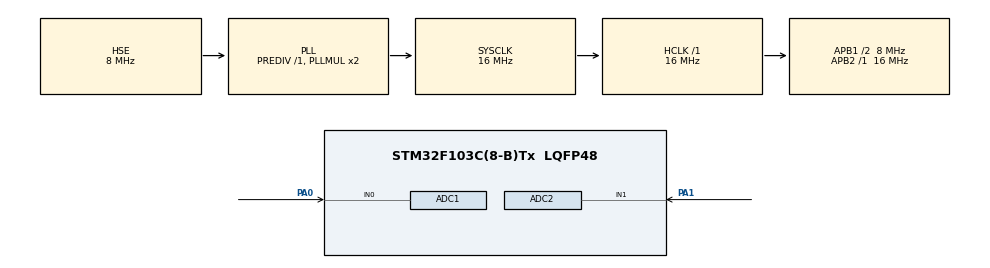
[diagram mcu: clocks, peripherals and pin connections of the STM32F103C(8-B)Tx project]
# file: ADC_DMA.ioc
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ADC1.Channel-0\#ChannelRegularConversion=ADC_CHANNEL_0
ADC1.ContinuousConvMode=ENABLE
ADC1.Mode=ADC_DUALMODE_REGSIMULT
ADC1.NbrOfConversion=1
ADC1.NbrOfConversionFlag=1
ADC1.Rank-0\#ChannelRegularConversion=1
ADC1.SamplingTime-0\#ChannelRegularConversion=ADC_SAMPLETIME_239CYCLES_5
ADC1.master=1
ADC2.Channel-0\#ChannelRegularConversion=ADC_CHANNEL_1
ADC2.ContinuousConvMode=ENABLE
ADC2.Mode=ADC_DUALMODE_REGSIMULT
ADC2.NbrOfConversionFlag=1
ADC2.Rank-0\#ChannelRegularConversion=1
ADC2.SamplingTime-0\#ChannelRegularConversion=ADC_SAMPLETIME_239CYCLES_5
Dma.ADC1.0.Direction=DMA_PERIPH_TO_MEMORY
Dma.ADC1.0.Instance=DMA1_Channel1
Dma.ADC1.0.MemDataAlignment=DMA_MDATAALIGN_WORD
Dma.ADC1.0.MemInc=DMA_MINC_ENABLE
Dma.ADC1.0.Mode=DMA_NORMAL
Dma.ADC1.0.PeriphDataAlignment=DMA_PDATAALIGN_WORD
Dma.ADC1.0.PeriphInc=DMA_PINC_DISABLE
Dma.ADC1.0.Priority=DMA_PRIORITY_LOW
Dma.Request0=ADC1
Mcu.Family=STM32F1
Mcu.Name=STM32F103C(8-B)Tx
Mcu.Package=LQFP48
NVIC.DMA1_Channel1_IRQn=true\:0\:0\:false\:false\:true\:false\:true\:true
NVIC.PriorityGroup=NVIC_PRIORITYGROUP_4
NVIC.TIM3_IRQn=true\:0\:0\:false\:false\:true\:true\:true\:true
PA0-WKUP.Signal=ADCx_IN0
PA1.Signal=ADCx_IN1
PA13.Mode=Serial_Wire
PA13.Signal=SYS_JTMS-SWDIO
PA14.Mode=Serial_Wire
PA14.Signal=SYS_JTCK-SWCLK
PD0-OSC_IN.Mode=HSE-External-Oscillator
PD0-OSC_IN.Signal=RCC_OSC_IN
PD1-OSC_OUT.Mode=HSE-External-Oscillator
PD1-OSC_OUT.Signal=RCC_OSC_OUT
ProjectManager.HeapSize=0x200
ProjectManager.StackSize=0x400
ProjectManager.TargetToolchain=STM32CubeIDE
RCC.ADCPresc=RCC_ADCPCLK2_DIV4
RCC.AHBFreq_Value=16000000
RCC.APB1CLKDivider=RCC_HCLK_DIV2
RCC.APB1Freq_Value=8000000
RCC.APB1TimFreq_Value=16000000
RCC.APB2Freq_Value=16000000
RCC.APB2TimFreq_Value=16000000
RCC.HCLKFreq_Value=16000000
RCC.PLLSourceVirtual=RCC_PLLSOURCE_HSE
RCC.SYSCLKFreq_VALUE=16000000
RCC.SYSCLKSource=RCC_SYSCLKSOURCE_PLLCLK
RCC.USBFreq_Value=16000000
SH.ADCx_IN0.0=ADC1_IN0,IN0
SH.ADCx_IN1.0=ADC2_IN1,IN1
TIM3.Period=10000-1
TIM3.Prescaler=1600-1
VP_TIM3_VS_ClockSourceINT.Mode=Internal
board=custom

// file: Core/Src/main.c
/* USER CODE BEGIN Header */
/**
  ******************************************************************************
  * @file           : main.c
  * @brief          : Main program body
  ******************************************************************************
  * @attention
  *
  * Copyright (c) 2024 STMicroelectronics.
  * All rights reserved.
  *
  * This software is licensed under terms that can be found in the LICENSE file
  * in the root directory of this software component.
  * If no LICENSE file comes with this software, it is provided AS-IS.
  *
  ******************************************************************************
  */
/* USER CODE END Header */
#include "main.h"

/* USER CODE BEGIN Includes */
#include "math.h"
/* USER CODE END Includes */

ADC_HandleTypeDef hadc1;
ADC_HandleTypeDef hadc2;
DMA_HandleTypeDef hdma_adc1;

TIM_HandleTypeDef htim3;

/* USER CODE BEGIN PV */

typedef struct {
	float alpha;
	float out;
} FirstOrderIIR;

FirstOrderIIR filt;

uint32_t adcg[256];			// Receberá os dados do ADC via DMA
uint32_t contagem;

float veficaz;
float tp = 97;

//float alpha_test = 1.0f / (1.0f + (2.0f * M_PI * 60.0f / 15360.0f));  // Melhor valor de alpha (~0.97)
float alpha_test = 0.95f;

/* USER CODE END PV */

void SystemClock_Config(void);
static void MX_GPIO_Init(void);
static void MX_DMA_Init(void);
static void MX_ADC1_Init(void);
static void MX_ADC2_Init(void);
static void MX_TIM3_Init(void);
/* USER CODE BEGIN PFP */

float rms(float sinal[], int num);
void FirstOrderIIR_Init(FirstOrderIIR *filt, float alpha);
float FirsOrderIIR_Update(FirstOrderIIR *filt, float in);

/* USER CODE END PFP */

/* USER CODE BEGIN 0 */

void HAL_TIM_PeriodElapsedCallback(TIM_HandleTypeDef *htim) {
	if (htim == &htim3) {
		contagem++;
	}
}

float rms(float sinal[], int num) {
	float integral = 0;
	float rms = 0;

	int y;
	for (y = 0; y < num; y++) {
		integral += (sinal[y] * sinal[y]);
	}

	integral = integral / num;
	rms = sqrt(integral);

	return rms;
}

void FirstOrderIIR_Init(FirstOrderIIR *filt, float alpha) {
	if (alpha < 0.0f) {
		filt->alpha = 0.0f;
	} else if (alpha > 1.0f) {
		filt->alpha=1.0f;
	} else {
		filt->alpha = alpha;
	}

	filt->out = 0.0f;
}

float FirstOrderIIR_Update(FirstOrderIIR *filt, float in) {
	filt->out = (1.0f - filt->alpha) * in + filt->alpha * filt->out;
	return filt->out;
}

/* USER CODE END 0 */

int main(void)
{
  /* USER CODE BEGIN 1 */

	uint32_t adcgl[256];
	uint32_t leitura1[256];
	uint32_t leitura1_filter[256];
	uint32_t leitura2[256];

	uint8_t set;
	float va[256];

  /* USER CODE END 1 */

  /* MCU Configuration--------------------------------------------------------*/

  /* Reset of all peripherals, Initializes the Flash interface and the Systick. */
  HAL_Init();

  /* Configure the system clock */
  SystemClock_Config();

  /* Initialize all configured peripherals */
  MX_GPIO_Init();
  MX_DMA_Init();
  MX_ADC1_Init();
  MX_ADC2_Init();
  MX_TIM3_Init();
  /* USER CODE BEGIN 2 */

  HAL_TIM_Base_Start_IT(&htim3);						// Inicializa o Timer 3
  HAL_ADC_Start(&hadc2);								// Inicializa o ADC2
  HAL_ADCEx_MultiModeStart_DMA(&hadc1, adcg, 256);		// Inicializa o ADC1 multimode com DMA usando a variável adcg para armazenar os valores

  FirstOrderIIR_Init(&filt, alpha_test);

  /* USER CODE END 2 */

  /* Infinite loop */
  while (1)
  {

    /* USER CODE BEGIN 3 */

	  if (contagem == 1) {
		  contagem = 0;
		  HAL_ADC_Stop(&hadc2);
		  HAL_ADCEx_MultiModeStop_DMA(&hadc1);
		  HAL_ADC_Start(&hadc2);
		  HAL_ADCEx_MultiModeStart_DMA(&hadc1, adcg, 256);
		  set = 1;
	  }

	  if (set == 1) {
		  for (int i = 0; i < 256; i++) {
			  adcgl[i] = adcg[i];
			  leitura1[i] = adcgl[i] & 0x0000ffff;		// Guarda em leitura1 somente os 16 bits a direita
			  leitura2[i] = adcgl[i] >> 16;				// Desloca 16bits a direita para guardar em leitura2

			  leitura1_filter[i] = FirstOrderIIR_Update(&filt, leitura1[i]);
		  }

		  for (int i = 0; i < 256; i++) {
			  va[i] = leitura1_filter[i];
			  va[i] = (((va[i])*(3.3/4095))-1.65) * tp;
		  }

		  veficaz = rms(va,256);

		  set = 0;
	  }
  }
  /* USER CODE END 3 */
}

void SystemClock_Config(void)
{
  RCC_OscInitTypeDef RCC_OscInitStruct = {0};
  RCC_ClkInitTypeDef RCC_ClkInitStruct = {0};
  RCC_PeriphCLKInitTypeDef PeriphClkInit = {0};

  /** Initializes the RCC Oscillators according to the specified parameters
  * in the RCC_OscInitTypeDef structure.
  */
  RCC_OscInitStruct.OscillatorType = RCC_OSCILLATORTYPE_HSE;
  RCC_OscInitStruct.HSEState = RCC_HSE_ON;
  RCC_OscInitStruct.HSEPredivValue = RCC_HSE_PREDIV_DIV1;
  RCC_OscInitStruct.HSIState = RCC_HSI_ON;
  RCC_OscInitStruct.PLL.PLLState = RCC_PLL_ON;
  RCC_OscInitStruct.PLL.PLLSource = RCC_PLLSOURCE_HSE;
  RCC_OscInitStruct.PLL.PLLMUL = RCC_PLL_MUL2;
  if (HAL_RCC_OscConfig(&RCC_OscInitStruct) != HAL_OK)
  {
    Error_Handler();
  }

  /** Initializes the CPU, AHB and APB buses clocks
  */
  RCC_ClkInitStruct.ClockType = RCC_CLOCKTYPE_HCLK|RCC_CLOCKTYPE_SYSCLK
                              |RCC_CLOCKTYPE_PCLK1|RCC_CLOCKTYPE_PCLK2;
  RCC_ClkInitStruct.SYSCLKSource = RCC_SYSCLKSOURCE_PLLCLK;
  RCC_ClkInitStruct.AHBCLKDivider = RCC_SYSCLK_DIV1;
  RCC_ClkInitStruct.APB1CLKDivider = RCC_HCLK_DIV2;
  RCC_ClkInitStruct.APB2CLKDivider = RCC_HCLK_DIV1;

  if (HAL_RCC_ClockConfig(&RCC_ClkInitStruct, FLASH_LATENCY_0) != HAL_OK)
  {
    Error_Handler();
  }
  PeriphClkInit.PeriphClockSelection = RCC_PERIPHCLK_ADC;
  PeriphClkInit.AdcClockSelection = RCC_ADCPCLK2_DIV4;
  if (HAL_RCCEx_PeriphCLKConfig(&PeriphClkInit) != HAL_OK)
  {
    Error_Handler();
  }
}

static void MX_ADC1_Init(void)
{

  ADC_MultiModeTypeDef multimode = {0};
  ADC_ChannelConfTypeDef sConfig = {0};

  /** Common config
  */
  hadc1.Instance = ADC1;
  hadc1.Init.ScanConvMode = ADC_SCAN_DISABLE;
  hadc1.Init.ContinuousConvMode = ENABLE;
  hadc1.Init.DiscontinuousConvMode = DISABLE;
  hadc1.Init.ExternalTrigConv = ADC_SOFTWARE_START;
  hadc1.Init.DataAlign = ADC_DATAALIGN_RIGHT;
  hadc1.Init.NbrOfConversion = 1;
  if (HAL_ADC_Init(&hadc1) != HAL_OK)
  {
    Error_Handler();
  }

  /** Configure the ADC multi-mode
  */
  multimode.Mode = ADC_DUALMODE_REGSIMULT;
  if (HAL_ADCEx_MultiModeConfigChannel(&hadc1, &multimode) != HAL_OK)
  {
    Error_Handler();
  }

  /** Configure Regular Channel
  */
  sConfig.Channel = ADC_CHANNEL_0;
  sConfig.Rank = ADC_REGULAR_RANK_1;
  sConfig.SamplingTime = ADC_SAMPLETIME_239CYCLES_5;
  if (HAL_ADC_ConfigChannel(&hadc1, &sConfig) != HAL_OK)
  {
    Error_Handler();
  }

}

static void MX_ADC2_Init(void)
{

  ADC_ChannelConfTypeDef sConfig = {0};

  /** Common config
  */
  hadc2.Instance = ADC2;
  hadc2.Init.ScanConvMode = ADC_SCAN_DISABLE;
  hadc2.Init.ContinuousConvMode = ENABLE;
  hadc2.Init.DiscontinuousConvMode = DISABLE;
  hadc2.Init.ExternalTrigConv = ADC_SOFTWARE_START;
  hadc2.Init.DataAlign = ADC_DATAALIGN_RIGHT;
  hadc2.Init.NbrOfConversion = 1;
  if (HAL_ADC_Init(&hadc2) != HAL_OK)
  {
    Error_Handler();
  }

  /** Configure Regular Channel
  */
  sConfig.Channel = ADC_CHANNEL_1;
  sConfig.Rank = ADC_REGULAR_RANK_1;
  sConfig.SamplingTime = ADC_SAMPLETIME_239CYCLES_5;
  if (HAL_ADC_ConfigChannel(&hadc2, &sConfig) != HAL_OK)
  {
    Error_Handler();
  }

}

static void MX_TIM3_Init(void)
{

  TIM_ClockConfigTypeDef sClockSourceConfig = {0};
  TIM_MasterConfigTypeDef sMasterConfig = {0};

  htim3.Instance = TIM3;
  htim3.Init.Prescaler = 1600-1;
  htim3.Init.CounterMode = TIM_COUNTERMODE_UP;
  htim3.Init.Period = 10000-1;
  htim3.Init.ClockDivision = TIM_CLOCKDIVISION_DIV1;
  htim3.Init.AutoReloadPreload = TIM_AUTORELOAD_PRELOAD_DISABLE;
  if (HAL_TIM_Base_Init(&htim3) != HAL_OK)
  {
    Error_Handler();
  }
  sClockSourceConfig.ClockSource = TIM_CLOCKSOURCE_INTERNAL;
  if (HAL_TIM_ConfigClockSource(&htim3, &sClockSourceConfig) != HAL_OK)
  {
    Error_Handler();
  }
  sMasterConfig.MasterOutputTrigger = TIM_TRGO_RESET;
  sMasterConfig.MasterSlaveMode = TIM_MASTERSLAVEMODE_DISABLE;
  if (HAL_TIMEx_MasterConfigSynchronization(&htim3, &sMasterConfig) != HAL_OK)
  {
    Error_Handler();
  }

}

static void MX_DMA_Init(void)
{

  /* DMA controller clock enable */
  __HAL_RCC_DMA1_CLK_ENABLE();

  /* DMA interrupt init */
  /* DMA1_Channel1_IRQn interrupt configuration */
  HAL_NVIC_SetPriority(DMA1_Channel1_IRQn, 0, 0);
  HAL_NVIC_EnableIRQ(DMA1_Channel1_IRQn);

}

static void MX_GPIO_Init(void)
{

  /* GPIO Ports Clock Enable */
  __HAL_RCC_GPIOD_CLK_ENABLE();
  __HAL_RCC_GPIOA_CLK_ENABLE();

}

void Error_Handler(void)
{
  __disable_irq();
  while (1)
  {
  }
}
